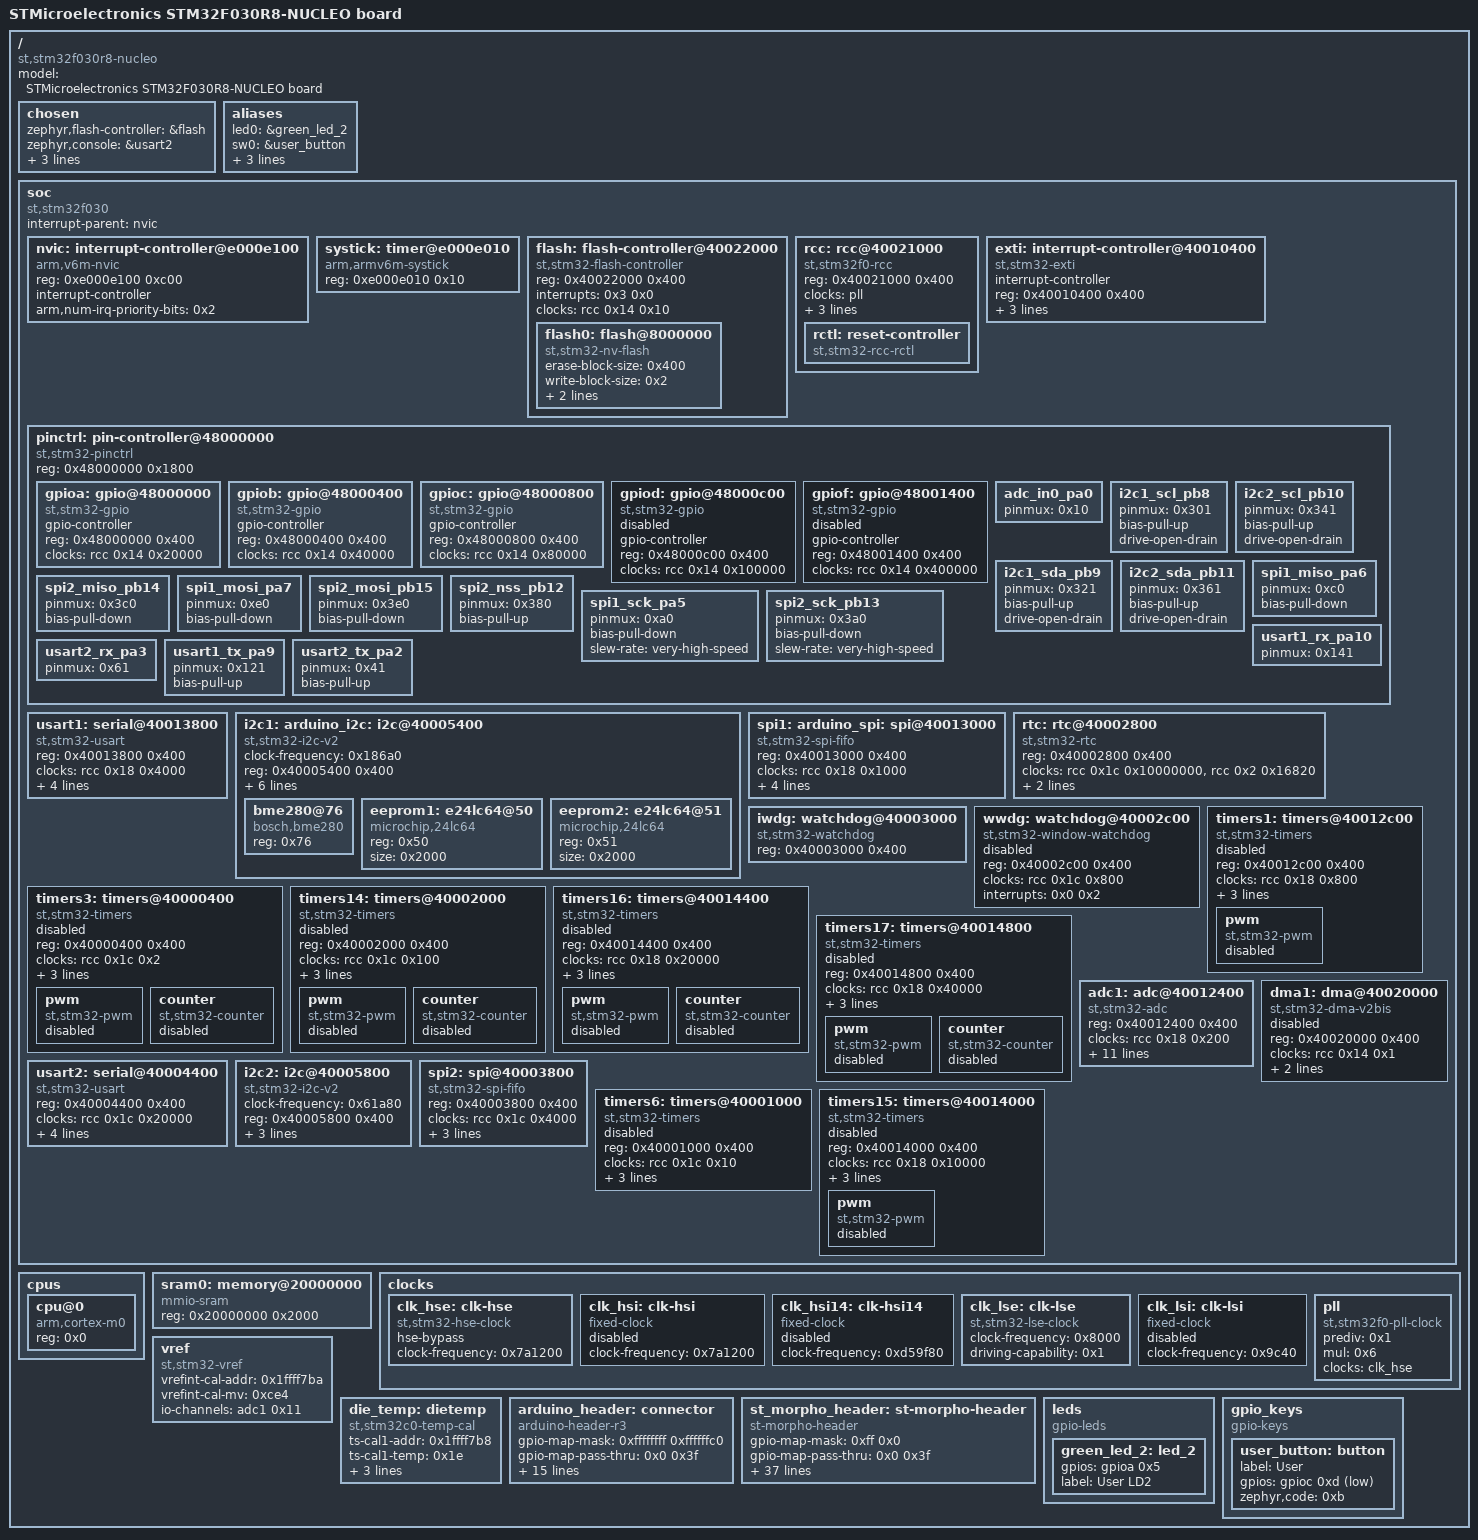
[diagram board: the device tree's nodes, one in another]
/dts-v1/;

/ {
	#address-cells = < 0x1 >;
	#size-cells = < 0x1 >;
	model = "STMicroelectronics STM32F030R8-NUCLEO board";
	compatible = "st,stm32f030r8-nucleo";
	chosen {
		zephyr,flash-controller = &flash;
		zephyr,console = &usart2;
		zephyr,shell-uart = &usart2;
		zephyr,sram = &sram0;
		zephyr,flash = &flash0;
	};
	aliases {
		led0 = &green_led_2;
		sw0 = &user_button;
		watchdog0 = &iwdg;
		die-temp0 = &die_temp;
		volt-sensor0 = &vref;
	};
	soc {
		#address-cells = < 0x1 >;
		#size-cells = < 0x1 >;
		compatible = "st,stm32f030", "st,stm32f0", "simple-bus";
		interrupt-parent = < &nvic >;
		ranges;
		nvic: interrupt-controller@e000e100 {
			#address-cells = < 0x1 >;
			compatible = "arm,v6m-nvic";
			reg = < 0xe000e100 0xc00 >;
			interrupt-controller;
			#interrupt-cells = < 0x2 >;
			arm,num-irq-priority-bits = < 0x2 >;
			phandle = < 0x1 >;
		};
		systick: timer@e000e010 {
			compatible = "arm,armv6m-systick";
			reg = < 0xe000e010 0x10 >;
		};
		flash: flash-controller@40022000 {
			compatible = "st,stm32-flash-controller", "st,stm32f1-flash-controller";
			reg = < 0x40022000 0x400 >;
			interrupts = < 0x3 0x0 >;
			clocks = < &rcc 0x14 0x10 >;
			#address-cells = < 0x1 >;
			#size-cells = < 0x1 >;
			flash0: flash@8000000 {
				compatible = "st,stm32-nv-flash", "soc-nv-flash";
				erase-block-size = < 0x400 >;
				write-block-size = < 0x2 >;
				max-erase-time = < 0x28 >;
				reg = < 0x8000000 0x10000 >;
			};
		};
		rcc: rcc@40021000 {
			compatible = "st,stm32f0-rcc";
			#clock-cells = < 0x2 >;
			reg = < 0x40021000 0x400 >;
			clocks = < &pll >;
			clock-frequency = < 0x2dc6c00 >;
			ahb-prescaler = < 0x1 >;
			apb1-prescaler = < 0x1 >;
			phandle = < 0x2 >;
			rctl: reset-controller {
				compatible = "st,stm32-rcc-rctl";
				#reset-cells = < 0x1 >;
				phandle = < 0x4 >;
			};
		};
		exti: interrupt-controller@40010400 {
			compatible = "st,stm32-exti";
			interrupt-controller;
			#interrupt-cells = < 0x1 >;
			#address-cells = < 0x1 >;
			reg = < 0x40010400 0x400 >;
			num-lines = < 0x10 >;
			interrupts = < 0x5 0x0 >, < 0x6 0x0 >, < 0x7 0x0 >;
			interrupt-names = "line0-1", "line2-3", "line4-15";
			line-ranges = < 0x0 0x2 >, < 0x2 0x2 >, < 0x4 0xc >;
		};
		pinctrl: pin-controller@48000000 {
			compatible = "st,stm32-pinctrl";
			#address-cells = < 0x1 >;
			#size-cells = < 0x1 >;
			reg = < 0x48000000 0x1800 >;
			gpioa: gpio@48000000 {
				compatible = "st,stm32-gpio";
				gpio-controller;
				#gpio-cells = < 0x2 >;
				reg = < 0x48000000 0x400 >;
				clocks = < &rcc 0x14 0x20000 >;
				phandle = < 0x18 >;
			};
			gpiob: gpio@48000400 {
				compatible = "st,stm32-gpio";
				gpio-controller;
				#gpio-cells = < 0x2 >;
				reg = < 0x48000400 0x400 >;
				clocks = < &rcc 0x14 0x40000 >;
				phandle = < 0xc >;
			};
			gpioc: gpio@48000800 {
				compatible = "st,stm32-gpio";
				gpio-controller;
				#gpio-cells = < 0x2 >;
				reg = < 0x48000800 0x400 >;
				clocks = < &rcc 0x14 0x80000 >;
				phandle = < 0x19 >;
			};
			gpiod: gpio@48000c00 {
				compatible = "st,stm32-gpio";
				gpio-controller;
				#gpio-cells = < 0x2 >;
				reg = < 0x48000c00 0x400 >;
				clocks = < &rcc 0x14 0x100000 >;
				status = "disabled";
				phandle = < 0x1a >;
			};
			gpiof: gpio@48001400 {
				compatible = "st,stm32-gpio";
				gpio-controller;
				#gpio-cells = < 0x2 >;
				reg = < 0x48001400 0x400 >;
				clocks = < &rcc 0x14 0x400000 >;
				status = "disabled";
				phandle = < 0x1b >;
			};
			adc_in0_pa0: adc_in0_pa0 {
				pinmux = < 0x10 >;
				phandle = < 0xd >;
			};
			i2c1_scl_pb8: i2c1_scl_pb8 {
				pinmux = < 0x301 >;
				bias-pull-up;
				drive-open-drain;
				phandle = < 0x7 >;
			};
			i2c2_scl_pb10: i2c2_scl_pb10 {
				pinmux = < 0x341 >;
				bias-pull-up;
				drive-open-drain;
				phandle = < 0x10 >;
			};
			i2c1_sda_pb9: i2c1_sda_pb9 {
				pinmux = < 0x321 >;
				bias-pull-up;
				drive-open-drain;
				phandle = < 0x8 >;
			};
			i2c2_sda_pb11: i2c2_sda_pb11 {
				pinmux = < 0x361 >;
				bias-pull-up;
				drive-open-drain;
				phandle = < 0x11 >;
			};
			spi1_miso_pa6: spi1_miso_pa6 {
				pinmux = < 0xc0 >;
				bias-pull-down;
				phandle = < 0xa >;
			};
			spi2_miso_pb14: spi2_miso_pb14 {
				pinmux = < 0x3c0 >;
				bias-pull-down;
				phandle = < 0x14 >;
			};
			spi1_mosi_pa7: spi1_mosi_pa7 {
				pinmux = < 0xe0 >;
				bias-pull-down;
				phandle = < 0xb >;
			};
			spi2_mosi_pb15: spi2_mosi_pb15 {
				pinmux = < 0x3e0 >;
				bias-pull-down;
				phandle = < 0x15 >;
			};
			spi2_nss_pb12: spi2_nss_pb12 {
				pinmux = < 0x380 >;
				bias-pull-up;
				phandle = < 0x12 >;
			};
			spi1_sck_pa5: spi1_sck_pa5 {
				pinmux = < 0xa0 >;
				bias-pull-down;
				slew-rate = "very-high-speed";
				phandle = < 0x9 >;
			};
			spi2_sck_pb13: spi2_sck_pb13 {
				pinmux = < 0x3a0 >;
				bias-pull-down;
				slew-rate = "very-high-speed";
				phandle = < 0x13 >;
			};
			usart1_rx_pa10: usart1_rx_pa10 {
				pinmux = < 0x141 >;
				phandle = < 0x6 >;
			};
			usart2_rx_pa3: usart2_rx_pa3 {
				pinmux = < 0x61 >;
				phandle = < 0xf >;
			};
			usart1_tx_pa9: usart1_tx_pa9 {
				pinmux = < 0x121 >;
				bias-pull-up;
				phandle = < 0x5 >;
			};
			usart2_tx_pa2: usart2_tx_pa2 {
				pinmux = < 0x41 >;
				bias-pull-up;
				phandle = < 0xe >;
			};
		};
		usart1: serial@40013800 {
			compatible = "st,stm32-usart", "st,stm32-uart";
			reg = < 0x40013800 0x400 >;
			clocks = < &rcc 0x18 0x4000 >;
			resets = < &rctl 0x18e >;
			interrupts = < 0x1b 0x0 >;
			status = "okay";
			pinctrl-0 = < &usart1_tx_pa9 &usart1_rx_pa10 >;
			pinctrl-names = "default";
			current-speed = < 0x1c200 >;
		};
		i2c1: arduino_i2c: i2c@40005400 {
			compatible = "st,stm32-i2c-v2";
			clock-frequency = < 0x186a0 >;
			#address-cells = < 0x1 >;
			#size-cells = < 0x0 >;
			reg = < 0x40005400 0x400 >;
			clocks = < &rcc 0x1c 0x200000 >, < &rcc 0x6 0x12430 >;
			interrupts = < 0x17 0x0 >;
			interrupt-names = "combined";
			status = "okay";
			pinctrl-0 = < &i2c1_scl_pb8 &i2c1_sda_pb9 >;
			pinctrl-names = "default";
			timings = < 0x7a1200 0x186a0 0x10420f13 >, < 0xf42400 0x186a0 0x30420f13 >, < 0x2dc6c00 0x186a0 0xb0420f13 >;
			bme280@76 {
				compatible = "bosch,bme280";
				reg = < 0x76 >;
				status = "okay";
			};
			eeprom1: e24lc64@50 {
				compatible = "microchip,24lc64";
				reg = < 0x50 >;
				size = < 0x2000 >;
				status = "okay";
			};
			eeprom2: e24lc64@51 {
				compatible = "microchip,24lc64";
				reg = < 0x51 >;
				size = < 0x2000 >;
				status = "okay";
			};
		};
		spi1: arduino_spi: spi@40013000 {
			compatible = "st,stm32-spi-fifo", "st,stm32-spi";
			#address-cells = < 0x1 >;
			#size-cells = < 0x0 >;
			reg = < 0x40013000 0x400 >;
			clocks = < &rcc 0x18 0x1000 >;
			interrupts = < 0x19 0x3 >;
			status = "okay";
			pinctrl-0 = < &spi1_sck_pa5 &spi1_miso_pa6 &spi1_mosi_pa7 >;
			pinctrl-names = "default";
			cs-gpios = < &gpiob 0x6 0x11 >;
		};
		rtc: rtc@40002800 {
			compatible = "st,stm32-rtc";
			reg = < 0x40002800 0x400 >;
			clocks = < &rcc 0x1c 0x10000000 >, < &rcc 0x2 0x16820 >;
			interrupts = < 0x2 0x0 >;
			prescaler = < 0x8000 >;
			status = "okay";
		};
		iwdg: watchdog@40003000 {
			compatible = "st,stm32-watchdog";
			reg = < 0x40003000 0x400 >;
			status = "okay";
		};
		wwdg: watchdog@40002c00 {
			compatible = "st,stm32-window-watchdog";
			reg = < 0x40002c00 0x400 >;
			clocks = < &rcc 0x1c 0x800 >;
			interrupts = < 0x0 0x2 >;
			status = "disabled";
		};
		timers1: timers@40012c00 {
			compatible = "st,stm32-timers";
			reg = < 0x40012c00 0x400 >;
			clocks = < &rcc 0x18 0x800 >;
			resets = < &rctl 0x18b >;
			interrupts = < 0xd 0x0 >, < 0xe 0x0 >;
			interrupt-names = "brk_up_trg_com", "cc";
			st,prescaler = < 0x0 >;
			status = "disabled";
			pwm {
				compatible = "st,stm32-pwm";
				status = "disabled";
				#pwm-cells = < 0x3 >;
			};
		};
		timers3: timers@40000400 {
			compatible = "st,stm32-timers";
			reg = < 0x40000400 0x400 >;
			clocks = < &rcc 0x1c 0x2 >;
			resets = < &rctl 0x201 >;
			interrupts = < 0x10 0x0 >;
			interrupt-names = "global";
			st,prescaler = < 0x0 >;
			status = "disabled";
			pwm {
				compatible = "st,stm32-pwm";
				status = "disabled";
				#pwm-cells = < 0x3 >;
			};
			counter {
				compatible = "st,stm32-counter";
				status = "disabled";
			};
		};
		timers14: timers@40002000 {
			compatible = "st,stm32-timers";
			reg = < 0x40002000 0x400 >;
			clocks = < &rcc 0x1c 0x100 >;
			resets = < &rctl 0x208 >;
			interrupts = < 0x13 0x0 >;
			interrupt-names = "global";
			st,prescaler = < 0x0 >;
			status = "disabled";
			pwm {
				compatible = "st,stm32-pwm";
				status = "disabled";
				#pwm-cells = < 0x3 >;
			};
			counter {
				compatible = "st,stm32-counter";
				status = "disabled";
			};
		};
		timers16: timers@40014400 {
			compatible = "st,stm32-timers";
			reg = < 0x40014400 0x400 >;
			clocks = < &rcc 0x18 0x20000 >;
			resets = < &rctl 0x191 >;
			interrupts = < 0x15 0x0 >;
			interrupt-names = "global";
			st,prescaler = < 0x0 >;
			status = "disabled";
			pwm {
				compatible = "st,stm32-pwm";
				status = "disabled";
				#pwm-cells = < 0x3 >;
			};
			counter {
				compatible = "st,stm32-counter";
				status = "disabled";
			};
		};
		timers17: timers@40014800 {
			compatible = "st,stm32-timers";
			reg = < 0x40014800 0x400 >;
			clocks = < &rcc 0x18 0x40000 >;
			resets = < &rctl 0x192 >;
			interrupts = < 0x16 0x0 >;
			interrupt-names = "global";
			st,prescaler = < 0x0 >;
			status = "disabled";
			pwm {
				compatible = "st,stm32-pwm";
				status = "disabled";
				#pwm-cells = < 0x3 >;
			};
			counter {
				compatible = "st,stm32-counter";
				status = "disabled";
			};
		};
		adc1: adc@40012400 {
			compatible = "st,stm32-adc";
			reg = < 0x40012400 0x400 >;
			clocks = < &rcc 0x18 0x200 >;
			interrupts = < 0xc 0x0 >;
			status = "okay";
			#io-channel-cells = < 0x1 >;
			temp-channel = < 0x10 >;
			vref-channel = < 0x11 >;
			resolutions = < 0x60630c 0x51630c 0x42630c 0x33630c >;
			sampling-times = < 0x2 0x8 0xe 0x1d 0x2a 0x38 0x48 0xf0 >;
			num-sampling-time-common-channels = < 0x1 >;
			pinctrl-0 = < &adc_in0_pa0 >;
			pinctrl-names = "default";
			st,adc-clock-source = < 0x1 >;
			st,adc-prescaler = < 0x4 >;
			phandle = < 0x17 >;
		};
		dma1: dma@40020000 {
			compatible = "st,stm32-dma-v2bis";
			#dma-cells = < 0x2 >;
			reg = < 0x40020000 0x400 >;
			clocks = < &rcc 0x14 0x1 >;
			interrupts = < 0x9 0x0 0xa 0x0 0xa 0x0 0xb 0x0 0xb 0x0 >;
			status = "disabled";
		};
		usart2: serial@40004400 {
			compatible = "st,stm32-usart", "st,stm32-uart";
			reg = < 0x40004400 0x400 >;
			clocks = < &rcc 0x1c 0x20000 >;
			resets = < &rctl 0x211 >;
			interrupts = < 0x1c 0x0 >;
			status = "okay";
			pinctrl-0 = < &usart2_tx_pa2 &usart2_rx_pa3 >;
			pinctrl-names = "default";
			current-speed = < 0x1c200 >;
		};
		i2c2: i2c@40005800 {
			compatible = "st,stm32-i2c-v2";
			clock-frequency = < 0x61a80 >;
			#address-cells = < 0x1 >;
			#size-cells = < 0x0 >;
			reg = < 0x40005800 0x400 >;
			clocks = < &rcc 0x1c 0x400000 >;
			interrupts = < 0x18 0x0 >;
			interrupt-names = "combined";
			status = "okay";
			pinctrl-0 = < &i2c2_scl_pb10 &i2c2_sda_pb11 >;
			pinctrl-names = "default";
		};
		spi2: spi@40003800 {
			compatible = "st,stm32-spi-fifo", "st,stm32-spi";
			#address-cells = < 0x1 >;
			#size-cells = < 0x0 >;
			reg = < 0x40003800 0x400 >;
			clocks = < &rcc 0x1c 0x4000 >;
			interrupts = < 0x1a 0x3 >;
			status = "okay";
			pinctrl-0 = < &spi2_nss_pb12 &spi2_sck_pb13 &spi2_miso_pb14 &spi2_mosi_pb15 >;
			pinctrl-names = "default";
		};
		timers6: timers@40001000 {
			compatible = "st,stm32-timers";
			reg = < 0x40001000 0x400 >;
			clocks = < &rcc 0x1c 0x10 >;
			resets = < &rctl 0x204 >;
			interrupts = < 0x11 0x0 >;
			interrupt-names = "global";
			st,prescaler = < 0x0 >;
			status = "disabled";
		};
		timers15: timers@40014000 {
			compatible = "st,stm32-timers";
			reg = < 0x40014000 0x400 >;
			clocks = < &rcc 0x18 0x10000 >;
			resets = < &rctl 0x190 >;
			interrupts = < 0x14 0x0 >;
			interrupt-names = "global";
			st,prescaler = < 0x0 >;
			status = "disabled";
			pwm {
				compatible = "st,stm32-pwm";
				status = "disabled";
				#pwm-cells = < 0x3 >;
			};
		};
	};
	cpus {
		#address-cells = < 0x1 >;
		#size-cells = < 0x0 >;
		cpu@0 {
			device_type = "cpu";
			compatible = "arm,cortex-m0";
			reg = < 0x0 >;
		};
	};
	sram0: memory@20000000 {
		compatible = "mmio-sram";
		reg = < 0x20000000 0x2000 >;
	};
	clocks {
		clk_hse: clk-hse {
			#clock-cells = < 0x0 >;
			compatible = "st,stm32-hse-clock";
			status = "okay";
			hse-bypass;
			clock-frequency = < 0x7a1200 >;
			phandle = < 0x16 >;
		};
		clk_hsi: clk-hsi {
			#clock-cells = < 0x0 >;
			compatible = "fixed-clock";
			clock-frequency = < 0x7a1200 >;
			status = "disabled";
		};
		clk_hsi14: clk-hsi14 {
			#clock-cells = < 0x0 >;
			compatible = "fixed-clock";
			clock-frequency = < 0xd59f80 >;
			status = "disabled";
		};
		clk_lse: clk-lse {
			#clock-cells = < 0x0 >;
			compatible = "st,stm32-lse-clock";
			clock-frequency = < 0x8000 >;
			driving-capability = < 0x1 >;
			status = "okay";
		};
		clk_lsi: clk-lsi {
			#clock-cells = < 0x0 >;
			compatible = "fixed-clock";
			clock-frequency = < 0x9c40 >;
			status = "disabled";
		};
		pll: pll {
			#clock-cells = < 0x0 >;
			compatible = "st,stm32f0-pll-clock";
			status = "okay";
			prediv = < 0x1 >;
			mul = < 0x6 >;
			clocks = < &clk_hse >;
			phandle = < 0x3 >;
		};
	};
	vref: vref {
		compatible = "st,stm32-vref";
		vrefint-cal-addr = < 0x1ffff7ba >;
		vrefint-cal-mv = < 0xce4 >;
		io-channels = < &adc1 0x11 >;
		status = "okay";
	};
	die_temp: dietemp {
		compatible = "st,stm32c0-temp-cal";
		ts-cal1-addr = < 0x1ffff7b8 >;
		ts-cal1-temp = < 0x1e >;
		ntc;
		ts-cal-vrefanalog = < 0xce4 >;
		io-channels = < &adc1 0x10 >;
		status = "okay";
	};
	arduino_header: connector {
		compatible = "arduino-header-r3";
		#gpio-cells = < 0x2 >;
		gpio-map-mask = < 0xffffffff 0xffffffc0 >;
		gpio-map-pass-thru = < 0x0 0x3f >;
		gpio-map = < 0x0 0x0 &gpioa 0x0 0x0 >, < 0x1 0x0 &gpioa 0x1 0x0 >, < 0x2 0x0 &gpioa 0x4 0x0 >, < 0x3 0x0 &gpiob 0x0 0x0 >, < 0x4 0x0 &gpioc 0x1 0x0 >, < 0x5 0x0 &gpioc 0x0 0x0 >, < 0x6 0x0 &gpioa 0x3 0x0 >, < 0x7 0x0 &gpioa 0x2 0x0 >, < 0x8 0x0 &gpioa 0xa 0x0 >, < 0x9 0x0 &gpiob 0x3 0x0 >, < 0xa 0x0 &gpiob 0x5 0x0 >, < 0xb 0x0 &gpiob 0x4 0x0 >, < 0xc 0x0 &gpiob 0xa 0x0 >, < 0xd 0x0 &gpioa 0x8 0x0 >, < 0xe 0x0 &gpioa 0x9 0x0 >, < 0xf 0x0 &gpioc 0x7 0x0 >, < 0x10 0x0 &gpiob 0x6 0x0 >, < 0x11 0x0 &gpioa 0x7 0x0 >, < 0x12 0x0 &gpioa 0x6 0x0 >, < 0x13 0x0 &gpioa 0x5 0x0 >, < 0x14 0x0 &gpiob 0x9 0x0 >, < 0x15 0x0 &gpiob 0x8 0x0 >;
	};
	st_morpho_header: st-morpho-header {
		compatible = "st-morpho-header";
		#gpio-cells = < 0x2 >;
		gpio-map-mask = < 0xff 0x0 >;
		gpio-map-pass-thru = < 0x0 0x3f >;
		gpio-map = < 0x0 0x0 &gpioc 0xa 0x0 >, < 0x1 0x0 &gpioc 0xb 0x0 >, < 0x2 0x0 &gpioc 0xc 0x0 >, < 0x3 0x0 &gpiod 0x2 0x0 >, < 0x8 0x0 &gpiof 0x6 0x0 >, < 0xa 0x0 &gpiof 0x7 0x0 >, < 0xc 0x0 &gpioa 0xd 0x0 >, < 0xe 0x0 &gpioa 0xe 0x0 >, < 0x10 0x0 &gpioa 0xf 0x0 >, < 0x14 0x0 &gpiob 0x7 0x0 >, < 0x16 0x0 &gpioc 0xd 0x0 >, < 0x18 0x0 &gpioc 0xe 0x0 >, < 0x1a 0x0 &gpioc 0xf 0x0 >, < 0x1b 0x0 &gpioa 0x0 0x0 >, < 0x1c 0x0 &gpiof 0x0 0x0 >, < 0x1d 0x0 &gpioa 0x1 0x0 >, < 0x1e 0x0 &gpiof 0x1 0x0 >, < 0x1f 0x0 &gpioa 0x4 0x0 >, < 0x21 0x0 &gpiob 0x0 0x0 >, < 0x22 0x0 &gpioc 0x2 0x0 >, < 0x23 0x0 &gpioc 0x1 0x0 >, < 0x24 0x0 &gpioc 0x3 0x0 >, < 0x25 0x0 &gpioc 0x0 0x0 >, < 0x48 0x0 &gpioc 0x9 0x0 >, < 0x49 0x0 &gpioc 0x8 0x0 >, < 0x4a 0x0 &gpiob 0x8 0x0 >, < 0x4b 0x0 &gpioc 0x6 0x0 >, < 0x4c 0x0 &gpiob 0x9 0x0 >, < 0x4d 0x0 &gpioc 0x5 0x0 >, < 0x52 0x0 &gpioa 0x5 0x0 >, < 0x53 0x0 &gpioa 0xc 0x0 >, < 0x54 0x0 &gpioa 0x6 0x0 >, < 0x55 0x0 &gpioa 0xb 0x0 >, < 0x56 0x0 &gpioa 0x7 0x0 >, < 0x57 0x0 &gpiob 0xc 0x0 >, < 0x58 0x0 &gpiob 0x6 0x0 >, < 0x59 0x0 &gpiob 0xb 0x0 >, < 0x5a 0x0 &gpioc 0x7 0x0 >, < 0x5c 0x0 &gpioa 0x9 0x0 >, < 0x5d 0x0 &gpiob 0x2 0x0 >, < 0x5e 0x0 &gpioa 0x8 0x0 >, < 0x5f 0x0 &gpiob 0x1 0x0 >, < 0x60 0x0 &gpiob 0xa 0x0 >, < 0x61 0x0 &gpiob 0xf 0x0 >, < 0x62 0x0 &gpiob 0x4 0x0 >, < 0x63 0x0 &gpiob 0xe 0x0 >, < 0x64 0x0 &gpiob 0x5 0x0 >, < 0x65 0x0 &gpiob 0xd 0x0 >, < 0x66 0x0 &gpiob 0x3 0x0 >, < 0x68 0x0 &gpioa 0xa 0x0 >, < 0x69 0x0 &gpioc 0x4 0x0 >, < 0x6a 0x0 &gpioa 0x2 0x0 >, < 0x6b 0x0 &gpiof 0x5 0x0 >, < 0x6c 0x0 &gpioa 0x3 0x0 >, < 0x6d 0x0 &gpiof 0x4 0x0 >;
	};
	leds: leds {
		compatible = "gpio-leds";
		green_led_2: led_2 {
			gpios = < &gpioa 0x5 0x0 >;
			label = "User LD2";
		};
	};
	gpio_keys {
		compatible = "gpio-keys";
		user_button: button {
			label = "User";
			gpios = < &gpioc 0xd 0x1 >;
			zephyr,code = < 0xb >;
		};
	};
};
